# SAM9X75D2G device description
Architecture: ARM926EJ-S; Family: SAM9; Series: SAM9X7
Registers are 32-bit, read-write, reset 0x0 unless marked. A register's access mark holds for its fields unless they carry their own. Offsets are from the block's base; [hi:lo] are bit positions; {n}, {i} and the like mark numbered series; 'fields as' and 'values as' point back to an identical list.

## PMC — Power Management Controller
Instances: PMC 0xFFFFFC00
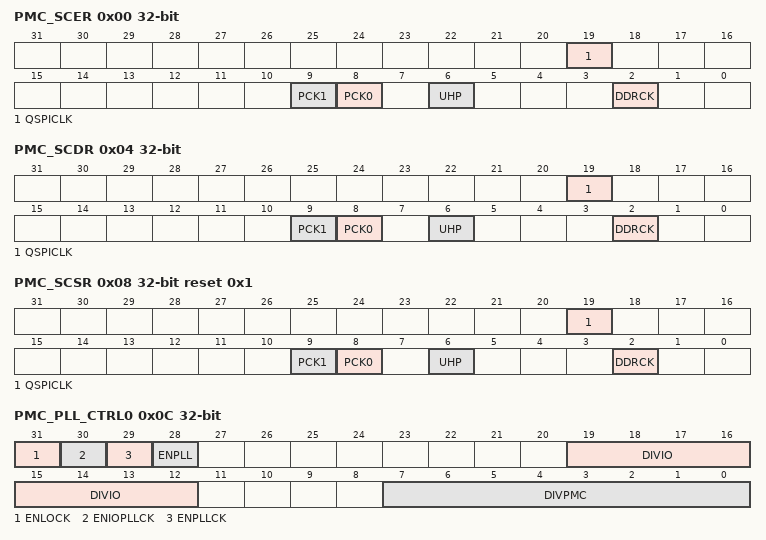
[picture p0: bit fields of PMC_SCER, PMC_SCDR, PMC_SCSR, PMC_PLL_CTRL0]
0x00 PMC_SCER wo reset not defined — System Clock Enable Register
  [19] QSPICLK — QSPI 2x Clock Enable
    0=No effect; 1=Enables the QSPI 2x clock
  [9] PCK1 — Programmable Clock 1 Output Enable
    0=No effect; 1=Enables the corresponding Programmable Clock output
  [8] PCK0 — Programmable Clock 0 Output Enable
    values as PCK1
  [6] UHP — USB Host OHCI Clocks Enable
    0=No effect; 1=Enables the UHP48M and UHP12M OHCI clocks
  [2] DDRCK — MPDDRC/SDRAMC Clock Enable
    0=No effect; 1=Enables the MPDDRC or SDRAMC clock
0x04 PMC_SCDR wo reset not defined (atomic clear of PMC_SCSR) — System Clock Disable Register
  [19] QSPICLK — QSPI 2x Clock Disable
    0=No effect; 1=Disables the QSPI 2x clock
  [9] PCK1 — Programmable Clock 1 Output Disable
    0=No effect; 1=Disables the corresponding Programmable Clock output
  [8] PCK0 — Programmable Clock 0 Output Disable
    values as PCK1
  [6] UHP — USB Host OHCI Clocks Disable
    0=No effect; 1=Disables the UHP48M and UHP12M OHCI clocks
  [2] DDRCK — MPDDRC/SDRAMC Clock Disable
    0=No effect; 1=Disables the MPDDRC or SDRAMC clock
0x08 PMC_SCSR ro reset 0x1 — System Clock Status Register
  [19] QSPICLK — QSPI 2x Clock Status
    0=The QSPI 2x clock is disabled; 1=The QSPI 2x clock is enabled
  [9] PCK1 — Programmable Clock 1 Output Status
    0=The corresponding Programmable Clock output is disabled; 1=The corresponding Programmable Clock output is enabled
  [8] PCK0 — Programmable Clock 0 Output Status
    values as PCK1
  [6] UHP — USB Host OHCI Clocks Status
    0=The UHP48M and UHP12M OHCI clocks are disabled; 1=The UHP48M and UHP12M OHCI clocks are enabled
  [2] DDRCK — MPDDRC/SDRAMC Clock Status
    0=The MPDDRC or SDRAMC clock is disabled; 1=The MPDDRC or SDRAMC clock is enabled
0x0C PMC_PLL_CTRL0 — PLL Control Register 0
  [31] ENLOCK — Enable PLL Lock
    0=The lock signal sent by the PLL is ignored. The PLL is considered as locked once the start-up time defined by PMC_PLL_UPDT.STUPTIM has elapsed.; 1=The PLL is considered as locked once the start-up time defined by PMC_PLL_UPDT.STUPTIM has elapsed and the lock signal sent by the PLL has risen
  [30] ENIOPLLCK — Enable PLL Clock for IO
    0=The clock generated by the PLL is not send to the IO; 1=The clock generated by the PLL is sent to the IO
  [29] ENPLLCK — Enable PLL Clock for PMC
    0=The clock generated by the PLL is not send to the IP_Acronym; 1=The clock generated by the PLL is sent to the IP_Acronym
  [28] ENPLL — Enable PLL
    0=The PLL is off; 1=The PLL is on
  [19:12] DIVIO — Divider for PAD
  [7:0] DIVPMC — Divider for PMC
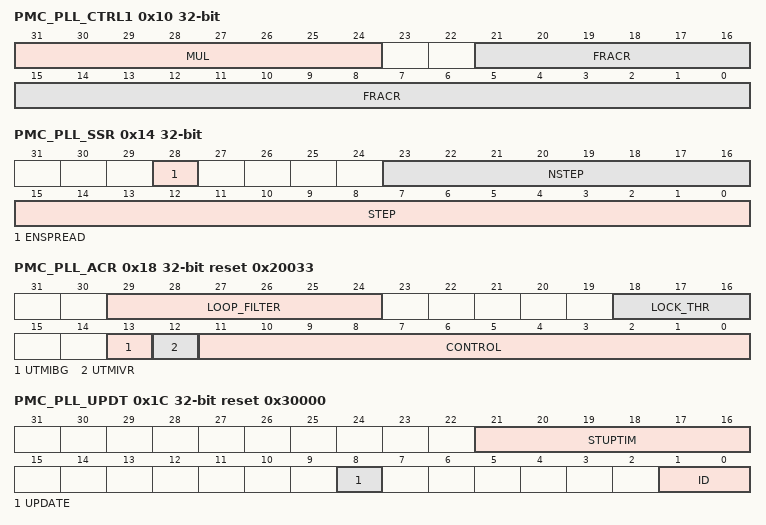
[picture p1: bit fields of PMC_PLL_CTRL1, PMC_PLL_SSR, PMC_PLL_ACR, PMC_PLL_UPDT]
0x10 PMC_PLL_CTRL1 — PLL Control Register 1
  [31:24] MUL — Multiplier Factor Value
  [21:0] FRACR — Fractional Loop Divider Setting
0x14 PMC_PLL_SSR — PLL Spread Spectrum Register
  [28] ENSPREAD — Spread Spectrum Enable
    0=The spread spectrum is not applied to the PLL; 1=The spread spectrum is applied to the PLL
  [23:16] NSTEP — Spread Spectrum Number of Steps
  [15:0] STEP — Spread Spectrum Step Size
0x18 PMC_PLL_ACR reset 0x20033 — PLL Analog Control Register
  [29:24] LOOP_FILTER — LOOP Filter Selection
  [18:16] LOCK_THR — PLL Lock Threshold Value Selection
  [13] UTMIBG — UPLL Bandgap Control
    0=The UPLL bandgap is switched off; 1=The UPLL bandgap is switched on
  [12] UTMIVR — UPLL Voltage Regulator Control
    0=The UPLL voltage regulator is switched off; 1=The UPLL voltage regulator is switched on
  [11:0] CONTROL — PLL CONTROL Value Selection
0x1C PMC_PLL_UPDT reset 0x30000 — PLL Update Register
  [21:16] STUPTIM — Start-up Time
    0=Only the lock of the PLL is considered to know the lock status of the PLL. If the lock of the PLL is not enabled, the lock never rises.
  [8] UPDATE — PLL Setting Update (write-only)
    0=No effect; 1=The PLL configuration written in PMC_PLL_CTRL0 and PMC_PLL_CTRL1 are applied to the PLL defined by the last ID written in the PMC_PLL_CTRL0 register
  [1:0] ID — PLL ID
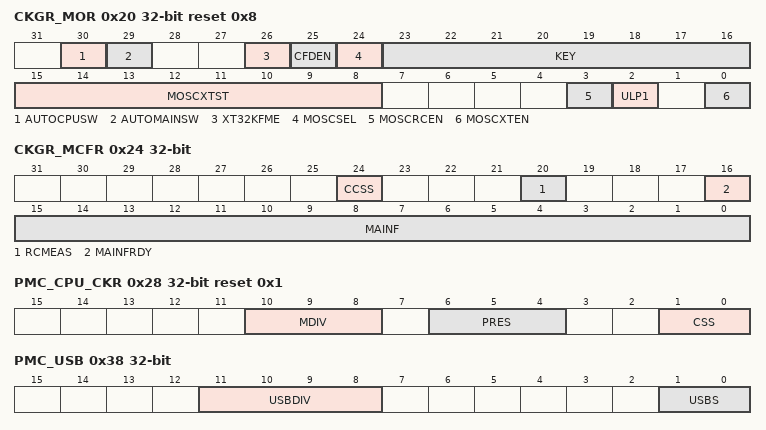
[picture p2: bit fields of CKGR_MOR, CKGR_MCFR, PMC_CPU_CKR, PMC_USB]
0x20 CKGR_MOR reset 0x8 — Main Oscillator Register
  [30] AUTOCPUSW — Automatic Processor Clock Source Switching
    0=A main crystal oscillator failure detection has no effect on the processor clock source selection; 1=If a main crystal oscillator failure is detected, the processor clock source selection automatically switches to the main clock
  [29] AUTOMAINSW — Automatic Main Clock Source Switching
    0=A main crystal oscillator failure detection has no effect on the main clock source selection; 1=If a main crystal oscillator failure is detected, the main clock source selection automatically switches to the main RC
  [26] XT32KFME — 32.768 kHz Crystal Oscillator Frequency Monitoring Enable
    0=The 32.768 kHz crystal oscillator frequency monitoring is disabled; 1=The 32.768 kHz crystal oscillator frequency monitoring is enabled
  [25] CFDEN — Clock Failure Detector Enable
    0=The clock failure detector is disabled; 1=The clock failure detector is enabled
  [24] MOSCSEL — Main Clock Oscillator Selection
    0=The main RC oscillator is selected; 1=The main crystal oscillator is selected
  [23:16] KEY — Write Access Password
    55=PASSWD (Writing any other value in this field aborts the write operation. Always reads as 0.)
  [15:8] MOSCXTST — Main Crystal Oscillator Start-up Time
  [3] MOSCRCEN — Main RC Oscillator Enable
    0=The main RC oscillator is disabled; 1=The main RC oscillator is enabled
  [2] ULP1 — ULP Mode 1 Command (write-only)
    0=No effect; 1=Puts the device in ULP mode 1
  [0] MOSCXTEN — Main Crystal Oscillator Enable
    0=The main crystal oscillator is disabled; 1=The main crystal oscillator is enabled or in bypass
0x24 CKGR_MCFR — Main Clock Frequency Register
  [24] CCSS — Counter Clock Source Selection
    0=The measured clock of the MAINF counter is the main RC oscillator; 1=The measured clock of the MAINF counter is the main crystal oscillator
  [20] RCMEAS — RC Oscillator Frequency Measure (write-only)
    0=No effect; 1=Restarts measuring of the frequency of MAINCK. MAINF carries the new frequency as soon as a low-to-high transition occurs on the MAINFRDY flag.
  [16] MAINFRDY — Main Clock Frequency Measure Ready
    0=MAINF value is not valid or the measured oscillator is disabled or a measure has just been started by means of RCMEAS; 1=The measured oscillator has been enabled previously and MAINF value is available
  [15:0] MAINF — Main Clock Frequency
0x28 PMC_CPU_CKR reset 0x1 — CPU Clock Register
  [10:8] MDIV — MCK Division
    0=EQ_PCK (MCK is FCLK divided by 1.); 1=PCK_DIV2 (MCK is FCLK divided by 2.); 2=PCK_DIV4 (MCK is FCLK divided by 4.); 3=PCK_DIV3 (MCK is FCLK divided by 3.); 4=PCK_DIV5 (MCK is FCLK divided by 5.)
  [6:4] PRES — Processor Clock Prescaler
    0=CLK_1 (Selected clock); 1=CLK_2 (Selected clock divided by 2); 2=CLK_4 (Selected clock divided by 4); 3=CLK_8 (Selected clock divided by 8); 4=CLK_16 (Selected clock divided by 16); 5=CLK_32 (Selected clock divided by 32); 6=CLK_64 (Selected clock divided by 64); 7=CLK_3 (Selected clock divided by 3)
  [1:0] CSS — MCK Source Selection
    0=SLOW_CLK (MD_SLCK is selected); 1=MAIN_CLK (MAINCK is selected); 2=PLLACK (PLLACK is selected); 3=UPLLCK (UPLL is selected)
0x38 PMC_USB — USB Clock Register
  [11:8] USBDIV — Divider for USB OHCI Clock
  [1:0] USBS — USB OHCI/EHCI Input Clock Selection
    0=PLLA (USB Clock Input is PLLACK.); 1=UPLL (USB Clock Input is UPLLCK.); 2=MAINXTAL (USB Clock Input is MAINXTALCK.)
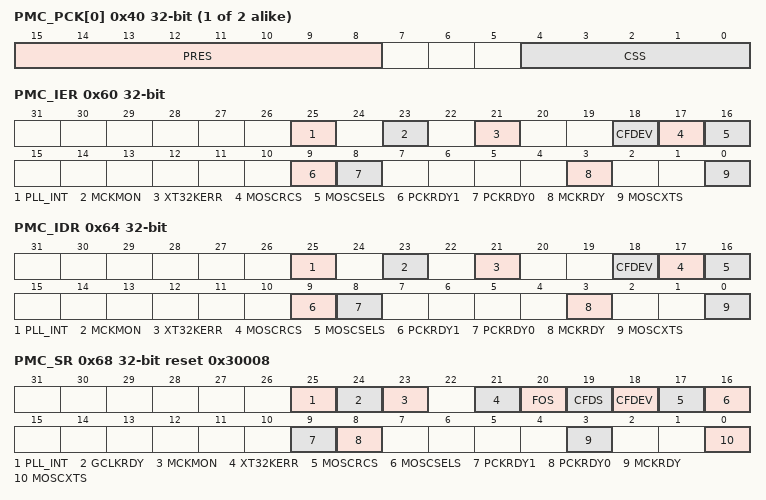
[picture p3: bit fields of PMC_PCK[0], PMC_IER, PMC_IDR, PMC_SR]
{0x40+4i} PMC_PCK[{i}] (i=0..1) — Programmable Clock Register x
  [15:8] PRES — Programmable Clock Prescaler
  [4:0] CSS — Programmable Clock Source Selection
    0=MD_SLOW_CLK (MD_SLCK is selected); 1=TD_SLOW_CLOCK (TD_SLCK is selected); 2=MAINCK (MAINCK is selected); 3=MCK (MCK is selected); 4=PLLA (PLLA is selected.); 5=UPLL (UPLL is selected.); 6=AUDIOPLL (Audio PLL is selected.)
0x60 PMC_IER wo reset not defined (atomic set of PMC_IMR) — Interrupt Enable Register
  [25] PLL_INT — PLL Interrupt Enable
  [23] MCKMON — Main System Bus Clock Clock Monitor Interrupt Enable
  [21] XT32KERR — 32.768 kHz Crystal Oscillator Error Interrupt Enable
  [18] CFDEV — Clock Failure Detector Event Interrupt Enable
  [17] MOSCRCS — Main RC Oscillator Status Interrupt Enable
  [16] MOSCSELS — Main Clock Source Oscillator Selection Status Interrupt Enable
  [9] PCKRDY1 — Programmable Clock Ready 1 Interrupt Enable
  [8] PCKRDY0 — Programmable Clock Ready 0 Interrupt Enable
  [3] MCKRDY — Main System Bus Clock Ready Interrupt Enable
  [0] MOSCXTS — Main Crystal Oscillator Status Interrupt Enable
0x64 PMC_IDR wo reset not defined (atomic clear of PMC_IMR) — Interrupt Disable Register
  [25] PLL_INT — PLL Interrupt Disable
  [23] MCKMON — Main System Bus Clock Clock Monitor Interrupt Disable
  [21] XT32KERR — 32.768 kHz Crystal Oscillator Error Interrupt Disable
  [18] CFDEV — Clock Failure Detector Event Interrupt Disable
  [17] MOSCRCS — Main RC Status Interrupt Disable
  [16] MOSCSELS — Main Clock Source Oscillator Selection Status Interrupt Disable
  [9] PCKRDY1 — Programmable Clock Ready 1 Interrupt Disable
  [8] PCKRDY0 — Programmable Clock Ready 0 Interrupt Disable
  [3] MCKRDY — Main System Bus Clock Ready Interrupt Disable
  [0] MOSCXTS — Main Crystal Oscillator Status Interrupt Disable
0x68 PMC_SR ro reset 0x30008 — Status Register
  [25] PLL_INT — PLL Interrupt Status
    0=No PLL interrupt has occurred; 1=A PLL interrupt has occurred. PLL interrupt is defined by the configuration of the PMC_IMR register.
  [24] GCLKRDY — GCLK Ready
    0=A GCLK is not ready to use (clock switching in progress); 1=All GCLKs are switched to their selected source clock and ready to use
  [23] MCKMON — Main System Bus Clock Clock Monitor Error
    0=Main System Bus Clock is correct or the CPU clock monitor is disabled; 1=Main System Bus is incorrect or has been incorrect for an elapsed period of time since the monitoring has been enabled
  [21] XT32KERR — Slow Crystal Oscillator Error
    0=The frequency of the 32.768 kHz crystal oscillator is correct (32.768 kHz +- 1%) or the monitoring is disabled; 1=The frequency of the 32.768 kHz crystal oscillator is incorrect or has been incorrect for an elapsed period of time since the monitoring has been enabled
  [20] FOS — Clock Failure Detector Fault Output Status
    0=The fault output of the clock failure detector is inactive; 1=The fault output of the clock failure detector is active. This status is cleared by writing a '1' to FOCLR in PMC_FOCR.
  [19] CFDS — Clock Failure Detector Status
    0=A clock failure of the main crystal oscillator clock is not detected; 1=A clock failure of the main crystal oscillator clock is detected
  [18] CFDEV — Clock Failure Detector Event
    0=No clock failure detection of the main crystal oscillator clock has occurred since the last read of PMC_SR; 1=At least one clock failure detection of the main crystal oscillator clock has occurred since the last read of PMC_SR
  [17] MOSCRCS — Main RC Oscillator Status
    0=Main RC oscillator is not stabilized; 1=Main RC oscillator is stabilized
  [16] MOSCSELS — Main Clock Source Oscillator Selection Status
    0=Selection is in progress; 1=Selection is done
  [9] PCKRDY1 — Programmable Clock Ready Status
    0=Programmable Clock x is not ready; 1=Programmable Clock x is ready
  [8] PCKRDY0 — Programmable Clock Ready Status
    values as PCKRDY1
  [3] MCKRDY — Main System Bus Clock Status
    0=Main System Bus Clock is not ready; 1=Main System Bus Clock is ready
  [0] MOSCXTS — Main Crystal Oscillator Status
    0=Main crystal oscillator is not stabilized; 1=Main crystal oscillator is stabilized
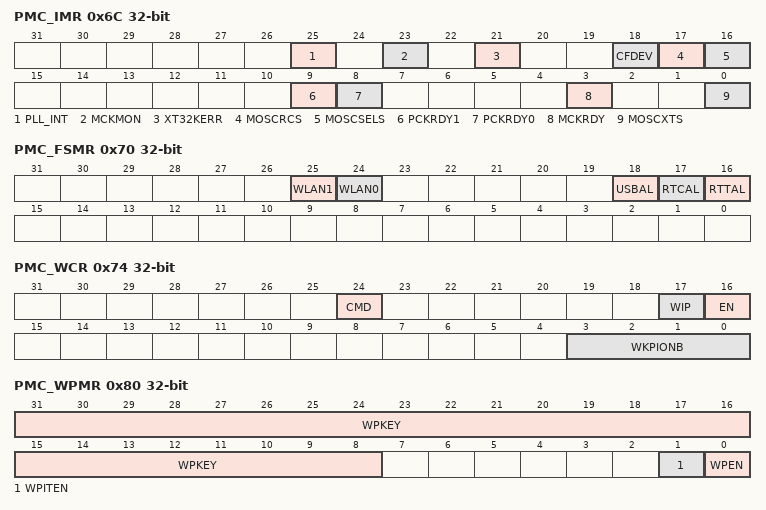
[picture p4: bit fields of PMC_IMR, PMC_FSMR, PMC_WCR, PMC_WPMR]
0x6C PMC_IMR ro — Interrupt Mask Register
  [25] PLL_INT — PLL Interrupt Mask
  [23] MCKMON — Main System Bus Clock Monitor Error Interrupt Mask
  [21] XT32KERR — 32.768 kHz Crystal Oscillator Error Interrupt Mask
  [18] CFDEV — Clock Failure Detector Event Interrupt Mask
  [17] MOSCRCS — Main RC Status Interrupt Mask
  [16] MOSCSELS — Main Clock Source Oscillator Selection Status Interrupt Mask
  [9] PCKRDY1 — Programmable Clock Ready 1 Interrupt Mask
  [8] PCKRDY0 — Programmable Clock Ready 0 Interrupt Mask
  [3] MCKRDY — Main System Bus Clock Ready Interrupt Mask
  [0] MOSCXTS — Main Crystal Oscillator Status Interrupt Mask
0x70 PMC_FSMR — Fast Startup Mode Register
  [25] WLAN1 — Wakeup on LAN[x]
    0=The Wakeup on LAN[x] alarm has no effect on the PMC; 1=The Wakeup on LAN[x] alarm enables a fast restart signal to the PMC
  [24] WLAN0 — Wakeup on LAN[x]
    values as WLAN1
  [18] USBAL — USB Alarm Enable
    0=The USB alarm has no effect on the IP_Acronym; 1=The USB alarm enables a fast restart signal to the IP_Acronym
  [17] RTCAL — RTC Alarm Enable
    0=The RTC alarm has no effect on the IP_Acronym; 1=The RTC alarm enables a fast restart signal to the IP_Acronym
  [16] RTTAL — RTT Alarm Enable
    0=The RTT alarm has no effect on the IP_Acronym; 1=The RTT alarm enables a fast restart signal to the IP_Acronym
0x74 PMC_WCR — Wakeup Control Register
  [24] CMD — Command
    0=Read mode; 1=Write mode
  [17] WIP — Wakeup Input Polarity
  [16] EN — Wakeup Input Enable
    0=The selected wakeup input has no effect on the IP_Acronym; 1=The selected wakeup input enables a fast restart signal to the IP_Acronym
  [3:0] WKPIONB — Wakeup Input Number
0x78 PMC_FOCR wo reset not defined — Fault Output Clear Register
  [0] FOCLR — Fault Output Clear
0x80 PMC_WPMR — Write Protection Mode Register
  [31:8] WPKEY — Write Protection Key
    0x504D43=PASSWD (Writing any other value in this field aborts the write operation of the WPEN bit. Always reads as 0.)
  [1] WPITEN — Write Protection Interrupt Enable
    0=Disables the write protection on interrupt registers if WPKEY corresponds to 0x504D43 ("PMC" in ASCII); 1=Enables the write protection on interrupt registers if WPKEY corresponds to 0x504D43 ("PMC" in ASCII)
  [0] WPEN — Write Protection Enable
    0=Disables the write protection if WPKEY corresponds to 0x504D43 ("PMC" in ASCII); 1=Enables the write protection if WPKEY corresponds to 0x504D43 ("PMC" in ASCII)
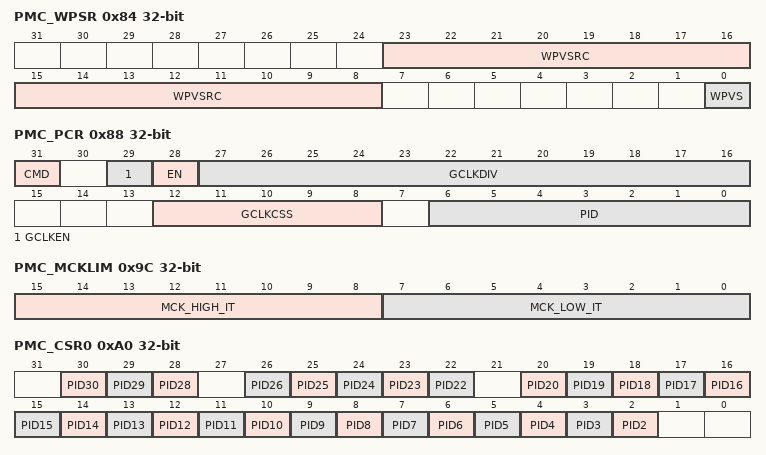
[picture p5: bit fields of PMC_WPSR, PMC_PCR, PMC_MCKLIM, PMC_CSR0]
0x84 PMC_WPSR ro — Write Protection Status Register
  [23:8] WPVSRC — Write Protection Violation Source
  [0] WPVS — Write Protection Violation Status
    0=No write protection violation has occurred since the last read of the PMC_WPSR; 1=A write protection violation has occurred since the last read of the PMC_WPSR. If this violation is an unauthorized attempt to write a protected register, the associated violation is reported into field WPVSRC.
0x88 PMC_PCR — Peripheral Control Register
  [31] CMD — Command
    0=Read mode; 1=Write mode
  [29] GCLKEN — Generic Clock Enable
    0=The selected generic clock is disabled; 1=The selected generic clock is enabled
  [28] EN — Enable
    0=Selected Peripheral clock is disabled; 1=Selected Peripheral clock is enabled
  [27:16] GCLKDIV — Generic Clock Division Ratio
  [12:8] GCLKCSS — Generic Clock Source Selection
    0=MD_SLOW_CLK (MD_SLCK is selected); 1=TD_SLOW_CLOCK (TD_SLCK is selected); 2=MAINCK (MAINCK is selected); 3=MCK (MCK is selected); 4=PLLA (PLLA is selected.); 5=UPLL (UPLL is selected.); 6=AUDIOPLL (Audio PLL is selected.); 8=PLLADIV2CLK (PLLADIV2CLK is selected.)
  [6:0] PID — Peripheral ID
0x9C PMC_MCKLIM — MCK Monitor Limits Register
  [15:8] MCK_HIGH_IT — MCK Monitoring High IT Limit
  [7:0] MCK_LOW_IT — MCK Monitoring Low IT Limit
0xA0 PMC_CSR0 ro — Peripheral Clock Status Register 0
  [all] fields
    0=The corresponding peripheral clock is disabled; 1=The corresponding peripheral clock is enabled
  [30] PID30 — Peripheral Clock 30 Status
  [29] PID29 — Peripheral Clock 29 Status
  [28] PID28 — Peripheral Clock 28 Status
  [n] PID{n} (n=22..26) — Peripheral Clock {n} Status
  [n] PID{n} (n=2..20) — Peripheral Clock {n} Status
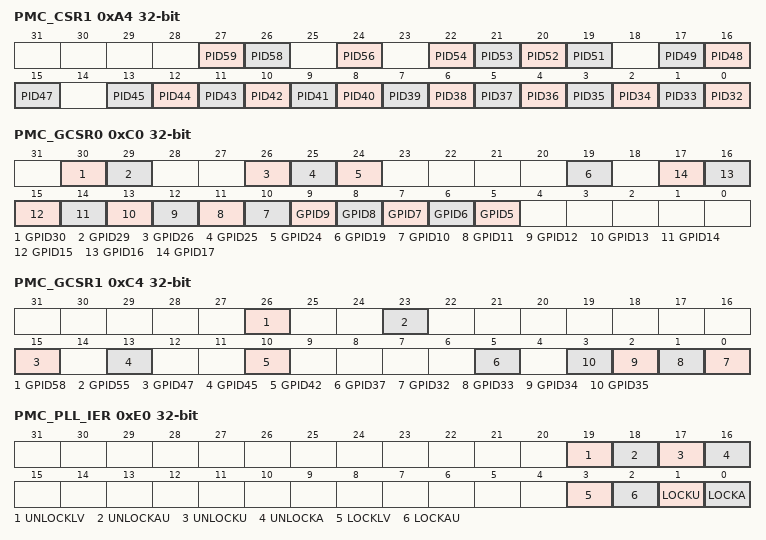
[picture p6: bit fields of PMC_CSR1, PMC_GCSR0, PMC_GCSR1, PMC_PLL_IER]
0xA4 PMC_CSR1 ro — Peripheral Clock Status Register 1
  [all] fields
    values as the fields of PMC_CSR0
  [27] PID59 — Peripheral Clock 59 Status
  [26] PID58 — Peripheral Clock 58 Status
  [24] PID56 — Peripheral Clock 56 Status
  [n-32] PID{n} (n=51..54) — Peripheral Clock {n} Status
  [17] PID49 — Peripheral Clock 49 Status
  [16] PID48 — Peripheral Clock 48 Status
  [15] PID47 — Peripheral Clock 47 Status
  [n-32] PID{n} (n=32..45) — Peripheral Clock {n} Status
0xC0 PMC_GCSR0 ro — Generic Clock Status Register 0
  [all] fields
    0=The corresponding Generic clock is disabled; 1=The corresponding Generic clock is enabled
  [30] GPID30 — Generic Clock 30 Status
  [29] GPID29 — Generic Clock 29 Status
  [26] GPID26 — Generic Clock 26 Status
  [25] GPID25 — Generic Clock 25 Status
  [24] GPID24 — Generic Clock 24 Status
  [19] GPID19 — Generic Clock 19 Status
  [n] GPID{n} (n=5..17) — Generic Clock {n} Status
0xC4 PMC_GCSR1 ro — Generic Clock Status Register 1
  [all] fields
    values as the fields of PMC_GCSR0
  [26] GPID58 — Generic Clock 58 Status
  [23] GPID55 — Generic Clock 55 Status
  [15] GPID47 — Generic Clock 47 Status
  [13] GPID45 — Generic Clock 45 Status
  [10] GPID42 — Generic Clock 42 Status
  [5] GPID37 — Generic Clock 37 Status
  [n-32] GPID{n} (n=32..35) — Generic Clock {n} Status
0xE0 PMC_PLL_IER wo reset not defined (atomic set of PMC_PLL_IMR) — PLL Interrupt Enable Register
  [19] UNLOCKLV — LVDS PLL Unlock Interrupt Enable
  [18] UNLOCKAU — AUDIO PLL Unlock Interrupt Enable
  [17] UNLOCKU — UPLL Unlock Interrupt Enable
  [16] UNLOCKA — PLLA Unlock Interrupt Enable
  [3] LOCKLV — LVDS PLL Lock Interrupt Enable
  [2] LOCKAU — AUDIO PLL Lock Interrupt Enable
  [1] LOCKU — UPLL Lock Interrupt Enable
  [0] LOCKA — PLLA Lock Interrupt Enable
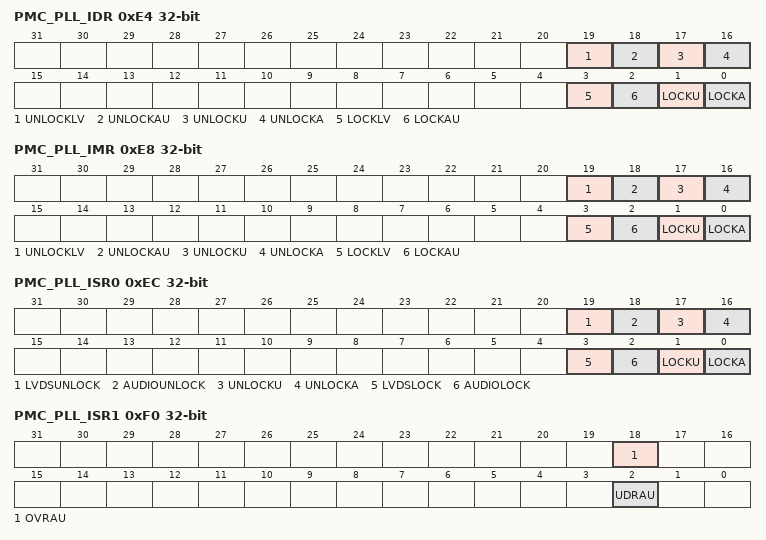
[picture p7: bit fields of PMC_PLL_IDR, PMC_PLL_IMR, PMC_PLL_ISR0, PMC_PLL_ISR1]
0xE4 PMC_PLL_IDR wo reset not defined (atomic clear of PMC_PLL_IMR) — PLL Interrupt Disable Register
  [19] UNLOCKLV — LVDS PLL Unlock Interrupt Disable
  [18] UNLOCKAU — AUDIO PLL Unlock Interrupt Disable
  [17] UNLOCKU — UPLL Unlock Interrupt Disable
  [16] UNLOCKA — PLLA Unlock Interrupt Disable
  [3] LOCKLV — LVDS PLL Lock Interrupt Disable
  [2] LOCKAU — AUDIO PLL Lock Interrupt Disable
  [1] LOCKU — UPLL Lock Interrupt Disable
  [0] LOCKA — PLLA Lock Interrupt Disable
0xE8 PMC_PLL_IMR ro — PLL Interrupt Mask Register
  [19] UNLOCKLV — LVDS PLL Unlock Interrupt Mask
  [18] UNLOCKAU — AUDIO PLL Unlock Interrupt Mask
  [17] UNLOCKU — UPLL Unlock Interrupt Mask
  [16] UNLOCKA — PLLA Unlock Interrupt Mask
  [3] LOCKLV — LVDS PLL Lock Interrupt Mask
  [2] LOCKAU — AUDIO PLL Lock Interrupt Mask
  [1] LOCKU — UPLL Lock Interrupt Mask
  [0] LOCKA — PLLA Lock Interrupt Mask
0xEC PMC_PLL_ISR0 ro — PLL Interrupt Status Register 0
  [19] LVDSUNLOCK — LVDS PLL Unlock Interrupt Status
    0=LVDS PLL is not unlocked; 1=LVDS PLL is unlocked
  [18] AUDIOUNLOCK — Audio PLL Unlock Interrupt Status
    0=Audio PLL is not unlocked; 1=Audio PLL is unlocked. To know the unlock type, the PMC_PISR1 register can be read.
  [17] UNLOCKU — UPLL Unlock Interrupt Status
    0=UPLL is not unlocked; 1=UPLL is unlocked. To know the unlock type, the PMC_PISR1 register can be read.
  [16] UNLOCKA — PLLA Unlock Interrupt Status
    0=PLLA is not unlocked; 1=PLLA is unlocked. To know the unlock type, the PMC_PISR1 register can be read.
  [3] LVDSLOCK — LVDS PLL Lock Interrupt Status
    0=LVDS PLL is not locked; 1=LVDS PLL is locked
  [2] AUDIOLOCK — Audio PLL Lock Interrupt Status
    0=Audio PLL is not locked; 1=Audio PLL is locked
  [1] LOCKU — UPLL Lock Interrupt Status
    0=UPLL is not locked; 1=UPLL is locked
  [0] LOCKA — PLLA Lock Interrupt Status
    0=PLLA is not locked; 1=PLLA is locked
0xF0 PMC_PLL_ISR1 ro — PLL Interrupt Status Register 1
  [18] OVRAU — AUDIO PLL Overflow
    0=AUDIO PLL is not in overflow state; 1=AUDIO PLL encountered an overflow
  [2] UDRAU — AUDIO PLL Underflow
    0=AUDIO PLL is not in underflow state; 1=AUDIO PLL encountered an underflow
